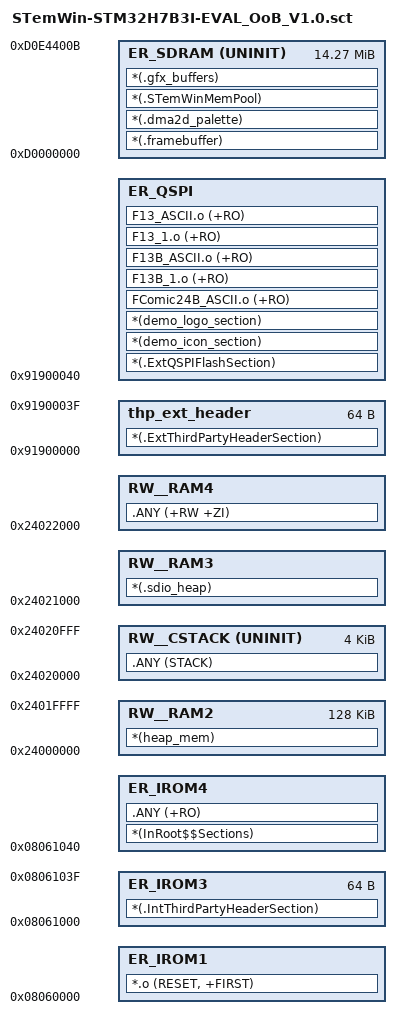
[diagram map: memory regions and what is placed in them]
; *************************************************************
; *** Scatter-Loading Description File generated by uVision ***
; *************************************************************

LR_IROM1 0x08060000   {    ; load region size_region
	ER_IROM1 0x08060000   {  ; load address = execution address
		*.o (RESET, +FIRST)
	}
	
}


LR_IROM3 0x08061000     {    ; load region size_region
	ER_IROM3 0x08061000  0x40 { 
		*(.IntThirdPartyHeaderSection)
		}
	ER_IROM4 0x08061040  {
		*(InRoot$$Sections)
		.ANY (+RO) 
	}
	RW__RAM2  0x24000000 0x20000{
	*(heap_mem)
	}
	RW__CSTACK  0x24020000 UNINIT 0x1000{
	.ANY (STACK)
	}
	RW__RAM3  0x24021000 {
	*(.sdio_heap)
	}
	RW__RAM4  0x24022000 {
	.ANY (+RW +ZI)
	}
	
	ER_SDRAM 0xD0000000 UNINIT 0xe4400c{ 
			*(.framebuffer)
			*(.dma2d_palette)
			*(.STemWinMemPool)
			*(.gfx_buffers)
		} 
}
LR_QSPI 0x91900000 0x800000 {
	thp_ext_header  0x91900000  0x40 { 
		*(.ExtThirdPartyHeaderSection) 
		}		
	ER_QSPI  0x91900040 {
		*(.ExtQSPIFlashSection)
		*(demo_icon_section)
		*(demo_logo_section)
		FComic24B_ASCII.o (+RO)
        F13B_1.o (+RO)
        F13B_ASCII.o (+RO)
        F13_1.o (+RO)
        F13_ASCII.o (+RO)
        }
}
